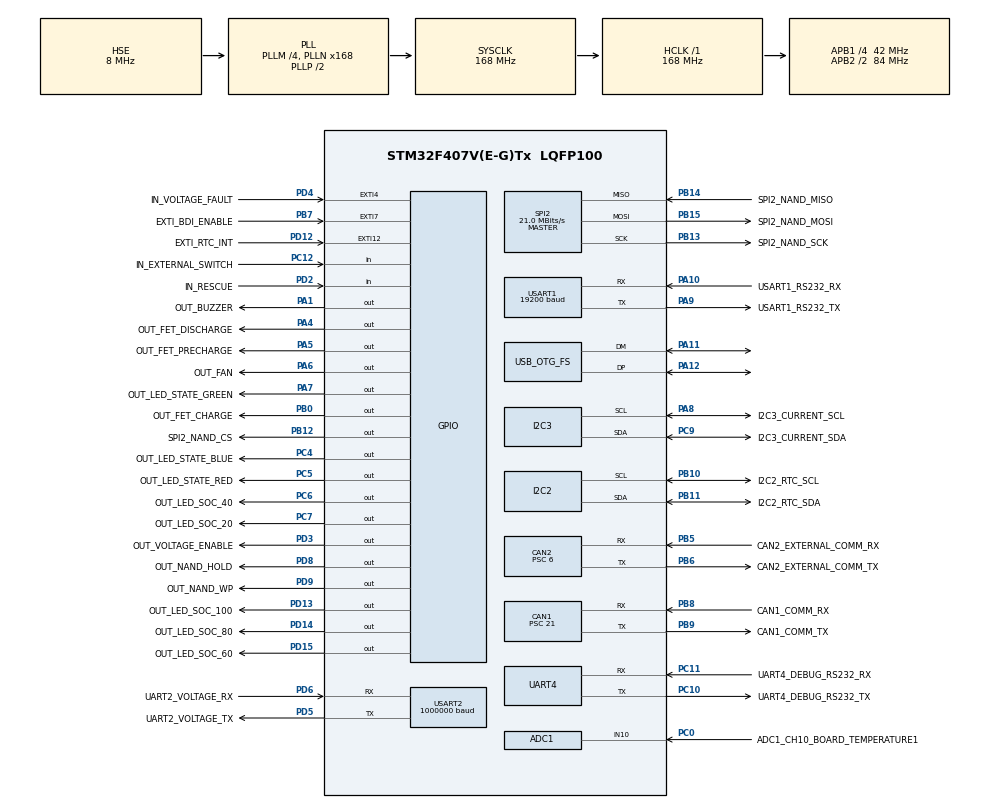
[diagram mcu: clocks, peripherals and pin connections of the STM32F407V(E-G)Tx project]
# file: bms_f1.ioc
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ADC1.Channel-6\#ChannelRegularConversion=ADC_CHANNEL_10
ADC1.NbrOfConversionFlag=1
ADC1.Rank-6\#ChannelRegularConversion=1
ADC1.SamplingTime-6\#ChannelRegularConversion=ADC_SAMPLETIME_3CYCLES
ADC1.master=1
CAN1.BS1=CAN_BS1_6TQ
CAN1.CalculateBaudRate=250000
CAN1.CalculateTimeBit=4000
CAN1.CalculateTimeQuantum=500.0
CAN1.Prescaler=21
CAN2.BS1=CAN_BS1_11TQ
CAN2.BS2=CAN_BS2_2TQ
CAN2.CalculateBaudRate=500000
CAN2.CalculateTimeBit=2000
CAN2.CalculateTimeQuantum=142.85714285714286
CAN2.Prescaler=6
Dma.ADC1.4.Direction=DMA_PERIPH_TO_MEMORY
Dma.ADC1.4.FIFOMode=DMA_FIFOMODE_DISABLE
Dma.ADC1.4.Instance=DMA2_Stream0
Dma.ADC1.4.MemDataAlignment=DMA_MDATAALIGN_HALFWORD
Dma.ADC1.4.MemInc=DMA_MINC_ENABLE
Dma.ADC1.4.Mode=DMA_NORMAL
Dma.ADC1.4.PeriphDataAlignment=DMA_PDATAALIGN_HALFWORD
Dma.ADC1.4.PeriphInc=DMA_PINC_DISABLE
Dma.ADC1.4.Priority=DMA_PRIORITY_LOW
Dma.Request0=USART2_TX
Dma.Request1=USART2_RX
Dma.Request2=SPI2_RX
Dma.Request3=SPI2_TX
Dma.Request4=ADC1
Dma.Request5=USART1_RX
Dma.Request6=USART1_TX
Dma.SPI2_RX.2.Direction=DMA_PERIPH_TO_MEMORY
Dma.SPI2_RX.2.FIFOMode=DMA_FIFOMODE_DISABLE
Dma.SPI2_RX.2.Instance=DMA1_Stream3
Dma.SPI2_RX.2.MemDataAlignment=DMA_MDATAALIGN_BYTE
Dma.SPI2_RX.2.MemInc=DMA_MINC_ENABLE
Dma.SPI2_RX.2.Mode=DMA_NORMAL
Dma.SPI2_RX.2.PeriphDataAlignment=DMA_PDATAALIGN_BYTE
Dma.SPI2_RX.2.PeriphInc=DMA_PINC_DISABLE
Dma.SPI2_RX.2.Priority=DMA_PRIORITY_LOW
Dma.SPI2_TX.3.Direction=DMA_MEMORY_TO_PERIPH
Dma.SPI2_TX.3.FIFOMode=DMA_FIFOMODE_DISABLE
Dma.SPI2_TX.3.Instance=DMA1_Stream4
Dma.SPI2_TX.3.MemDataAlignment=DMA_MDATAALIGN_BYTE
Dma.SPI2_TX.3.MemInc=DMA_MINC_ENABLE
Dma.SPI2_TX.3.Mode=DMA_NORMAL
Dma.SPI2_TX.3.PeriphDataAlignment=DMA_PDATAALIGN_BYTE
Dma.SPI2_TX.3.PeriphInc=DMA_PINC_DISABLE
Dma.SPI2_TX.3.Priority=DMA_PRIORITY_LOW
Dma.USART1_RX.5.Direction=DMA_PERIPH_TO_MEMORY
Dma.USART1_RX.5.FIFOMode=DMA_FIFOMODE_DISABLE
Dma.USART1_RX.5.Instance=DMA2_Stream2
Dma.USART1_RX.5.MemDataAlignment=DMA_MDATAALIGN_BYTE
Dma.USART1_RX.5.MemInc=DMA_MINC_ENABLE
Dma.USART1_RX.5.Mode=DMA_NORMAL
Dma.USART1_RX.5.PeriphDataAlignment=DMA_PDATAALIGN_BYTE
Dma.USART1_RX.5.PeriphInc=DMA_PINC_DISABLE
Dma.USART1_RX.5.Priority=DMA_PRIORITY_LOW
Dma.USART1_TX.6.Direction=DMA_MEMORY_TO_PERIPH
Dma.USART1_TX.6.FIFOMode=DMA_FIFOMODE_DISABLE
Dma.USART1_TX.6.Instance=DMA2_Stream7
Dma.USART1_TX.6.MemDataAlignment=DMA_MDATAALIGN_BYTE
Dma.USART1_TX.6.MemInc=DMA_MINC_ENABLE
Dma.USART1_TX.6.Mode=DMA_NORMAL
Dma.USART1_TX.6.PeriphDataAlignment=DMA_PDATAALIGN_BYTE
Dma.USART1_TX.6.PeriphInc=DMA_PINC_DISABLE
Dma.USART1_TX.6.Priority=DMA_PRIORITY_LOW
Dma.USART2_RX.1.Direction=DMA_PERIPH_TO_MEMORY
Dma.USART2_RX.1.FIFOMode=DMA_FIFOMODE_DISABLE
Dma.USART2_RX.1.Instance=DMA1_Stream5
Dma.USART2_RX.1.MemDataAlignment=DMA_MDATAALIGN_BYTE
Dma.USART2_RX.1.MemInc=DMA_MINC_ENABLE
Dma.USART2_RX.1.Mode=DMA_NORMAL
Dma.USART2_RX.1.PeriphDataAlignment=DMA_PDATAALIGN_BYTE
Dma.USART2_RX.1.PeriphInc=DMA_PINC_DISABLE
Dma.USART2_RX.1.Priority=DMA_PRIORITY_LOW
Dma.USART2_TX.0.Direction=DMA_MEMORY_TO_PERIPH
Dma.USART2_TX.0.FIFOMode=DMA_FIFOMODE_DISABLE
Dma.USART2_TX.0.Instance=DMA1_Stream6
Dma.USART2_TX.0.MemDataAlignment=DMA_MDATAALIGN_BYTE
Dma.USART2_TX.0.MemInc=DMA_MINC_ENABLE
Dma.USART2_TX.0.Mode=DMA_NORMAL
Dma.USART2_TX.0.PeriphDataAlignment=DMA_PDATAALIGN_BYTE
Dma.USART2_TX.0.PeriphInc=DMA_PINC_DISABLE
Dma.USART2_TX.0.Priority=DMA_PRIORITY_LOW
FREERTOS.Tasks01=unused_task,24,128,unUsedTask,Default,NULL,Dynamic,NULL,NULL
FREERTOS.configLIBRARY_MAX_SYSCALL_INTERRUPT_PRIORITY=5
FREERTOS.configTOTAL_HEAP_SIZE=20000
FREERTOS.configUSE_NEWLIB_REENTRANT=1
I2C2.I2C_Mode=I2C_Standard
I2C3.I2C_Mode=I2C_Fast
Mcu.Family=STM32F4
Mcu.Name=STM32F407V(E-G)Tx
Mcu.Package=LQFP100
NVIC.ADC_IRQn=true\:5\:0\:false\:false\:true\:true\:true\:true\:true
NVIC.CAN1_RX0_IRQn=true\:5\:0\:false\:false\:true\:true\:true\:true\:true
NVIC.CAN1_SCE_IRQn=true\:5\:0\:false\:false\:true\:true\:true\:true\:true
NVIC.CAN1_TX_IRQn=true\:5\:0\:false\:false\:true\:true\:true\:true\:true
NVIC.CAN2_RX0_IRQn=true\:5\:0\:false\:false\:true\:true\:true\:true\:true
NVIC.CAN2_RX1_IRQn=true\:5\:0\:false\:false\:true\:true\:true\:true\:true
NVIC.CAN2_SCE_IRQn=true\:5\:0\:false\:false\:true\:true\:true\:true\:true
NVIC.CAN2_TX_IRQn=true\:5\:0\:false\:false\:true\:true\:true\:true\:true
NVIC.DMA1_Stream3_IRQn=true\:5\:0\:false\:false\:true\:true\:false\:true\:true
NVIC.DMA1_Stream4_IRQn=true\:5\:0\:false\:false\:true\:true\:false\:true\:true
NVIC.DMA1_Stream5_IRQn=true\:5\:0\:false\:false\:true\:true\:false\:true\:true
NVIC.DMA1_Stream6_IRQn=true\:5\:0\:true\:false\:true\:true\:false\:true\:true
NVIC.DMA2_Stream0_IRQn=true\:5\:0\:false\:false\:true\:true\:false\:true\:true
NVIC.DMA2_Stream2_IRQn=true\:5\:0\:false\:false\:true\:true\:false\:true\:true
NVIC.DMA2_Stream7_IRQn=true\:5\:0\:false\:false\:true\:true\:false\:true\:true
NVIC.EXTI4_IRQn=true\:5\:0\:true\:false\:true\:true\:true\:true\:true
NVIC.EXTI9_5_IRQn=true\:5\:0\:false\:false\:true\:true\:true\:true\:true
NVIC.I2C2_ER_IRQn=true\:5\:0\:false\:false\:true\:true\:true\:true\:true
NVIC.OTG_FS_IRQn=true\:5\:0\:true\:false\:true\:true\:true\:true\:true
NVIC.PriorityGroup=NVIC_PRIORITYGROUP_4
NVIC.SPI2_IRQn=true\:5\:0\:false\:false\:true\:true\:true\:true\:true
NVIC.TIM6_DAC_IRQn=true\:5\:0\:false\:false\:true\:true\:true\:true\:true
NVIC.TIM7_IRQn=true\:15\:0\:false\:false\:true\:false\:false\:true\:true
NVIC.TimeBase=TIM7_IRQn
NVIC.TimeBaseIP=TIM7
NVIC.UART4_IRQn=true\:5\:0\:false\:false\:true\:true\:true\:true\:true
NVIC.USART1_IRQn=true\:5\:0\:false\:false\:true\:true\:true\:true\:true
NVIC.USART2_IRQn=true\:5\:0\:true\:false\:true\:true\:true\:true\:true
PA1.GPIO_Label=OUT_BUZZER
PA1.GPIO_ModeDefaultOutputPP=GPIO_MODE_OUTPUT_OD
PA1.GPIO_PuPd=GPIO_NOPULL
PA1.PinState=GPIO_PIN_SET
PA1.Signal=GPIO_Output
PA10.GPIO_Label=USART1_RS232_RX
PA10.GPIO_PuPd=GPIO_PULLUP
PA10.Mode=Asynchronous
PA10.Signal=USART1_RX
PA11.Mode=Device_Only
PA11.Signal=USB_OTG_FS_DM
PA12.Mode=Device_Only
PA12.Signal=USB_OTG_FS_DP
PA13.Mode=Trace_Asynchronous_SW
PA13.Signal=SYS_JTMS-SWDIO
PA14.Mode=Trace_Asynchronous_SW
PA14.Signal=SYS_JTCK-SWCLK
PA4.GPIO_Label=OUT_FET_DISCHARGE
PA4.GPIO_ModeDefaultOutputPP=GPIO_MODE_OUTPUT_OD
PA4.GPIO_PuPd=GPIO_NOPULL
PA4.PinState=GPIO_PIN_RESET
PA4.Signal=GPIO_Output
PA5.GPIO_Label=OUT_FET_PRECHARGE
PA5.GPIO_ModeDefaultOutputPP=GPIO_MODE_OUTPUT_OD
PA5.GPIO_PuPd=GPIO_NOPULL
PA5.PinState=GPIO_PIN_SET
PA5.Signal=GPIO_Output
PA6.GPIO_Label=OUT_FAN
PA6.GPIO_ModeDefaultOutputPP=GPIO_MODE_OUTPUT_OD
PA6.GPIO_PuPd=GPIO_NOPULL
PA6.GPIO_Speed=GPIO_SPEED_FREQ_LOW
PA6.PinState=GPIO_PIN_SET
PA6.Signal=GPIO_Output
PA7.GPIO_Label=OUT_LED_STATE_GREEN
PA7.GPIO_ModeDefaultOutputPP=GPIO_MODE_OUTPUT_OD
PA7.GPIO_PuPd=GPIO_NOPULL
PA7.Signal=GPIO_Output
PA8.GPIO_Label=I2C3_CURRENT_SCL
PA8.Mode=I2C
PA8.Signal=I2C3_SCL
PA9.GPIO_Label=USART1_RS232_TX
PA9.Mode=Asynchronous
PA9.Signal=USART1_TX
PB0.GPIO_Label=OUT_FET_CHARGE
PB0.GPIO_ModeDefaultOutputPP=GPIO_MODE_OUTPUT_OD
PB0.GPIO_PuPd=GPIO_NOPULL
PB0.Signal=GPIO_Output
PB10.GPIO_Label=I2C2_RTC_SCL
PB10.Mode=I2C
PB10.Signal=I2C2_SCL
PB11.GPIO_Label=I2C2_RTC_SDA
PB11.Mode=I2C
PB11.Signal=I2C2_SDA
PB12.GPIO_Label=SPI2_NAND_CS
PB12.GPIO_ModeDefaultOutputPP=GPIO_MODE_OUTPUT_OD
PB12.GPIO_PuPd=GPIO_NOPULL
PB12.GPIO_Speed=GPIO_SPEED_FREQ_VERY_HIGH
PB12.PinState=GPIO_PIN_SET
PB12.Signal=GPIO_Output
PB13.GPIO_Label=SPI2_NAND_SCK
PB13.Mode=Full_Duplex_Master
PB13.Signal=SPI2_SCK
PB14.GPIO_Label=SPI2_NAND_MISO
PB14.Mode=Full_Duplex_Master
PB14.Signal=SPI2_MISO
PB15.GPIO_Label=SPI2_NAND_MOSI
PB15.Mode=Full_Duplex_Master
PB15.Signal=SPI2_MOSI
PB3.Mode=Trace_Asynchronous_SW
PB3.Signal=SYS_JTDO-SWO
PB5.GPIO_Label=CAN2_EXTERNAL_COMM_RX
PB5.Mode=CAN_Activate
PB5.Signal=CAN2_RX
PB6.GPIO_Label=CAN2_EXTERNAL_COMM_TX
PB6.Mode=CAN_Activate
PB6.Signal=CAN2_TX
PB7.GPIO_Label=EXTI_BDI_ENABLE
PB7.GPIO_ModeDefaultEXTI=GPIO_MODE_IT_RISING
PB7.GPIO_PuPd=GPIO_NOPULL
PB7.Signal=GPXTI7
PB8.GPIO_Label=CAN1_COMM_RX
PB8.Mode=CAN_Activate
PB8.Signal=CAN1_RX
PB9.GPIO_Label=CAN1_COMM_TX
PB9.Mode=CAN_Activate
PB9.Signal=CAN1_TX
PC0.GPIO_Label=ADC1_CH10_BOARD_TEMPERATURE1
PC0.Signal=ADCx_IN10
PC10.GPIO_Label=UART4_DEBUG_RS232_TX
PC10.Mode=Asynchronous
PC10.Signal=UART4_TX
PC11.GPIO_Label=UART4_DEBUG_RS232_RX
PC11.Mode=Asynchronous
PC11.Signal=UART4_RX
PC12.GPIO_Label=IN_EXTERNAL_SWITCH
PC12.GPIO_PuPd=GPIO_PULLUP
PC12.Signal=GPIO_Input
PC4.GPIO_Label=OUT_LED_STATE_BLUE
PC4.GPIO_ModeDefaultOutputPP=GPIO_MODE_OUTPUT_OD
PC4.GPIO_PuPd=GPIO_NOPULL
PC4.Signal=GPIO_Output
PC5.GPIO_Label=OUT_LED_STATE_RED
PC5.GPIO_ModeDefaultOutputPP=GPIO_MODE_OUTPUT_OD
PC5.GPIO_PuPd=GPIO_NOPULL
PC5.GPIO_Speed=GPIO_SPEED_FREQ_LOW
PC5.PinState=GPIO_PIN_RESET
PC5.Signal=GPIO_Output
PC6.GPIO_Label=OUT_LED_SOC_40
PC6.GPIO_ModeDefaultOutputPP=GPIO_MODE_OUTPUT_OD
PC6.GPIO_PuPd=GPIO_NOPULL
PC6.PinState=GPIO_PIN_SET
PC6.Signal=GPIO_Output
PC7.GPIO_Label=OUT_LED_SOC_20
PC7.GPIO_ModeDefaultOutputPP=GPIO_MODE_OUTPUT_OD
PC7.GPIO_PuPd=GPIO_NOPULL
PC7.PinState=GPIO_PIN_SET
PC7.Signal=GPIO_Output
PC9.GPIO_Label=I2C3_CURRENT_SDA
PC9.Mode=I2C
PC9.Signal=I2C3_SDA
PD12.GPIO_Label=EXTI_RTC_INT
PD12.GPIO_PuPd=GPIO_PULLUP
PD12.Signal=GPXTI12
PD13.GPIO_Label=OUT_LED_SOC_100
PD13.GPIO_ModeDefaultOutputPP=GPIO_MODE_OUTPUT_OD
PD13.GPIO_PuPd=GPIO_NOPULL
PD13.PinState=GPIO_PIN_SET
PD13.Signal=GPIO_Output
PD14.GPIO_Label=OUT_LED_SOC_80
PD14.GPIO_ModeDefaultOutputPP=GPIO_MODE_OUTPUT_OD
PD14.GPIO_PuPd=GPIO_NOPULL
PD14.PinState=GPIO_PIN_SET
PD14.Signal=GPIO_Output
PD15.GPIO_Label=OUT_LED_SOC_60
PD15.GPIO_ModeDefaultOutputPP=GPIO_MODE_OUTPUT_OD
PD15.GPIO_PuPd=GPIO_NOPULL
PD15.PinState=GPIO_PIN_SET
PD15.Signal=GPIO_Output
PD2.GPIO_Label=IN_RESCUE
PD2.GPIO_PuPd=GPIO_PULLDOWN
PD2.Signal=GPIO_Input
PD3.GPIO_Label=OUT_VOLTAGE_ENABLE
PD3.Signal=GPIO_Output
PD4.GPIO_Label=IN_VOLTAGE_FAULT
PD4.GPIO_ModeDefaultEXTI=GPIO_MODE_IT_RISING_FALLING
PD4.Signal=GPXTI4
PD5.GPIO_Label=UART2_VOLTAGE_TX
PD5.Mode=Asynchronous
PD5.Signal=USART2_TX
PD6.GPIO_Label=UART2_VOLTAGE_RX
PD6.GPIO_PuPd=GPIO_PULLUP
PD6.Mode=Asynchronous
PD6.Signal=USART2_RX
PD8.GPIO_Label=OUT_NAND_HOLD
PD8.Signal=GPIO_Output
PD9.GPIO_Label=OUT_NAND_WP
PD9.PinState=GPIO_PIN_RESET
PD9.Signal=GPIO_Output
PH0-OSC_IN.Mode=HSE-External-Oscillator
PH0-OSC_IN.Signal=RCC_OSC_IN
PH1-OSC_OUT.Mode=HSE-External-Oscillator
PH1-OSC_OUT.Signal=RCC_OSC_OUT
ProjectManager.HeapSize=0x200
ProjectManager.StackSize=0x400
ProjectManager.TargetToolchain=STM32CubeIDE
RCC.48MHZClocksFreq_Value=48000000
RCC.AHBFreq_Value=168000000
RCC.APB1CLKDivider=RCC_HCLK_DIV4
RCC.APB1Freq_Value=42000000
RCC.APB1TimFreq_Value=84000000
RCC.APB2CLKDivider=RCC_HCLK_DIV2
RCC.APB2Freq_Value=84000000
RCC.APB2TimFreq_Value=168000000
RCC.CortexFreq_Value=168000000
RCC.HCLKFreq_Value=168000000
RCC.HSE_VALUE=8000000
RCC.HSI_VALUE=16000000
RCC.LSE_VALUE=32768
RCC.PLLM=4
RCC.PLLN=168
RCC.PLLQ=7
RCC.RCC_RTC_Clock_Source=RCC_RTCCLKSOURCE_LSI
RCC.RCC_RTC_Clock_SourceVirtual=RCC_RTCCLKSOURCE_LSE
RCC.SYSCLKFreq_VALUE=168000000
RCC.SYSCLKSource=RCC_SYSCLKSOURCE_PLLCLK
RCC.VCOOutputFreq_Value=336000000
RTC.Format=RTC_FORMAT_BIN
RTC.StoreOperation=RTC_STOREOPERATION_SET
RTC.WeekDay=RTC_WEEKDAY_SUNDAY
SH.ADCx_IN10.0=ADC1_IN10,IN10
SPI2.CalculateBaudRate=21.0 MBits/s
SPI2.Direction=SPI_DIRECTION_2LINES
SPI2.Mode=SPI_MODE_MASTER
SPI2.VirtualType=VM_MASTER
TIM6.AutoReloadPreload=TIM_AUTORELOAD_PRELOAD_ENABLE
TIM6.Period=999
TIM6.Prescaler=83
UART4.VirtualMode=Asynchronous
USART1.BaudRate=19200
USART1.VirtualMode=VM_ASYNC
USART2.BaudRate=1000000
USART2.VirtualMode=VM_ASYNC
USB_OTG_FS.VirtualMode=Device_Only
VP_FREERTOS_VS_CMSIS_V2.Mode=CMSIS_V2
VP_RTC_VS_RTC_Activate.Mode=RTC_Enabled
VP_RTC_VS_RTC_Calendar.Mode=RTC_Calendar
VP_SYS_VS_tim7.Mode=TIM7
VP_TIM6_VS_ClockSourceINT.Mode=Enable_Timer
board=custom

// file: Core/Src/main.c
/* USER CODE BEGIN Header */
/**
  ******************************************************************************
  * @file           : main.c
  * @brief          : Main program body
  ******************************************************************************
  * @attention
  *
  * Copyright (c) 2026 STMicroelectronics.
  * All rights reserved.
  *
  * This software is licensed under terms that can be found in the LICENSE file
  * in the root directory of this software component.
  * If no LICENSE file comes with this software, it is provided AS-IS.
  *
  ******************************************************************************
  */
/* USER CODE END Header */
#include "main.h"
#include "cmsis_os.h"
#include "adc.h"
#include "can.h"
#include "dma.h"
#include "i2c.h"
#include "rtc.h"
#include "spi.h"
#include "tim.h"
#include "usart.h"
#include "usb_otg.h"
#include "gpio.h"

void SystemClock_Config(void);
void MX_FREERTOS_Init(void);

/* USER CODE BEGIN 0 */
#if 0
/* USER CODE END 0 */

int main(void)
{

  /* USER CODE BEGIN 1 */
#endif
void MX_Init(void) {
  /* USER CODE END 1 */

  /* MCU Configuration--------------------------------------------------------*/

  /* Reset of all peripherals, Initializes the Flash interface and the Systick. */
  HAL_Init();

  /* Configure the system clock */
  SystemClock_Config();

  /* Initialize all configured peripherals */
  MX_GPIO_Init();
  MX_DMA_Init();
  MX_RTC_Init();
  MX_TIM6_Init();
  MX_ADC1_Init();
  MX_USART2_UART_Init();
  MX_USB_OTG_FS_PCD_Init();
  MX_CAN1_Init();
  MX_SPI2_Init();
  MX_CAN2_Init();
  MX_I2C2_Init();
  MX_I2C3_Init();
  MX_UART4_Init();
  MX_USART1_UART_Init();
  /* USER CODE BEGIN 2 */
#if 0
  /* USER CODE END 2 */

  /* Init scheduler */
  osKernelInitialize();  /* Call init function for freertos objects (in cmsis_os2.c) */
  MX_FREERTOS_Init();

  /* Start scheduler */
  osKernelStart();

  /* We should never get here as control is now taken by the scheduler */

  /* Infinite loop */
  while (1)
  {

    /* USER CODE BEGIN 3 */
  }
#endif
  /* USER CODE END 3 */
}

void SystemClock_Config(void)
{
  RCC_OscInitTypeDef RCC_OscInitStruct = {0};
  RCC_ClkInitTypeDef RCC_ClkInitStruct = {0};

  /** Configure the main internal regulator output voltage
  */
  __HAL_RCC_PWR_CLK_ENABLE();
  __HAL_PWR_VOLTAGESCALING_CONFIG(PWR_REGULATOR_VOLTAGE_SCALE1);

  /** Initializes the RCC Oscillators according to the specified parameters
  * in the RCC_OscInitTypeDef structure.
  */
  RCC_OscInitStruct.OscillatorType = RCC_OSCILLATORTYPE_LSI|RCC_OSCILLATORTYPE_HSE;
  RCC_OscInitStruct.HSEState = RCC_HSE_ON;
  RCC_OscInitStruct.LSIState = RCC_LSI_ON;
  RCC_OscInitStruct.PLL.PLLState = RCC_PLL_ON;
  RCC_OscInitStruct.PLL.PLLSource = RCC_PLLSOURCE_HSE;
  RCC_OscInitStruct.PLL.PLLM = 4;
  RCC_OscInitStruct.PLL.PLLN = 168;
  RCC_OscInitStruct.PLL.PLLP = RCC_PLLP_DIV2;
  RCC_OscInitStruct.PLL.PLLQ = 7;
  if (HAL_RCC_OscConfig(&RCC_OscInitStruct) != HAL_OK)
  {
    Error_Handler();
  }

  /** Initializes the CPU, AHB and APB buses clocks
  */
  RCC_ClkInitStruct.ClockType = RCC_CLOCKTYPE_HCLK|RCC_CLOCKTYPE_SYSCLK
                              |RCC_CLOCKTYPE_PCLK1|RCC_CLOCKTYPE_PCLK2;
  RCC_ClkInitStruct.SYSCLKSource = RCC_SYSCLKSOURCE_PLLCLK;
  RCC_ClkInitStruct.AHBCLKDivider = RCC_SYSCLK_DIV1;
  RCC_ClkInitStruct.APB1CLKDivider = RCC_HCLK_DIV4;
  RCC_ClkInitStruct.APB2CLKDivider = RCC_HCLK_DIV2;

  if (HAL_RCC_ClockConfig(&RCC_ClkInitStruct, FLASH_LATENCY_5) != HAL_OK)
  {
    Error_Handler();
  }
}

void HAL_TIM_PeriodElapsedCallback(TIM_HandleTypeDef *htim)
{
  if (htim->Instance == TIM7)
  {
    HAL_IncTick();
  }
}

void Error_Handler(void)
{
  __disable_irq();
  while (1)
  {
  }
}

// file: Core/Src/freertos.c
/* USER CODE BEGIN Header */
/**
  ******************************************************************************
  * File Name          : freertos.c
  * Description        : Code for freertos applications
  ******************************************************************************
  * @attention
  *
  * Copyright (c) 2026 STMicroelectronics.
  * All rights reserved.
  *
  * This software is licensed under terms that can be found in the LICENSE file
  * in the root directory of this software component.
  * If no LICENSE file comes with this software, it is provided AS-IS.
  *
  ******************************************************************************
  */
/* USER CODE END Header */

#include "FreeRTOS.h"
#include "task.h"
#include "main.h"
#include "cmsis_os.h"

/* Definitions for unused_task */
osThreadId_t unused_taskHandle;
const osThreadAttr_t unused_task_attributes = {
  .name = "unused_task",
  .stack_size = 128 * 4,
  .priority = (osPriority_t) osPriorityNormal,
};

void unUsedTask(void *argument);

void MX_FREERTOS_Init(void); /* (MISRA C 2004 rule 8.1) */

void MX_FREERTOS_Init(void) {

  /* Create the thread(s) */
  /* creation of unused_task */
  unused_taskHandle = osThreadNew(unUsedTask, NULL, &unused_task_attributes);

}

void unUsedTask(void *argument)
{
  for(;;)
  {
    osDelay(1);
  }
}
